# R40 register map
Vendor: Allwinner; Series: R40; File version: 0.1
CPU: CA7 0, little endian, MPU, FPU, double-precision FPU, 0 interrupt priority bits
Registers are 32-bit, read-write, reset 0x0 unless marked. A register's access mark holds for its fields unless they carry their own. Offsets are from the block's base; lines under a group give offsets from that group; [hi:lo] are bit positions; {n}, {i} and the like mark numbered series; 'fields as' and 'values as' point back to an identical list; <NAME> marks a mode.

## Memory map
0x01C00000 SYS_CTRL
0x01C02000 DMA
0x01C03000 NDFC
0x01C04000 TSC
0x01C05000 SPI0
0x01C06000 SPI1
0x01C09000 CSI0
0x01C0B000 EMAC
0x01C0F000 SMHC0
0x01C10000 SMHC1
0x01C11000 SMHC2
0x01C12000 SMHC3
0x01C15000 CE_NS
0x01C15800 CE_S
0x01C17000 SPI2
0x01C19000 USB1_HOST
0x01C1C000 USB2_HOST
0x01C1D000 CSI1
0x01C1F000 SPI3
0x01C20000 CCU
0x01C20400 RTC
0x01C20800 PIO
0x01C20C00 Timer
0x01C21000 OWA
0x01C21400 AC97
0x01C21800 CIR0
0x01C21C00 CIR1
0x01C22000 I2S/PCM0
0x01C22400 I2S/PCM1
0x01C22800 I2S/PCM2(for_HDMI)
0x01C22C00 Audio_Codec
0x01C23000 KeyPad
0x01C23400 PWM
0x01C24400 KEYADC
0x01C24C00 Thermal_Sensor
0x01C25000 RTP
0x01C25C00 CPU_Configuration
{0x1C28000+0x400*n} UART{n} (n=0..7)
0x01C2A000 PS2-0
0x01C2A400 PS2-1
0x01C2AC00 TWI0
0x01C2B000 TWI1
0x01C2B400 TWI2
0x01C2B800 TWI3
0x01C2C000 TWI4
0x01C2C400 SCR
0x01C30000 TVD_TOP
0x01C31000 TVD0
0x01C32000 TVD1
0x01C33000 TVD2
0x01C34000 TVD3
0x01C50000 GMAC
0x01C60000 High_Speed_Timer
0x01C70000 TCON_TOP
0x01C71000 TCON_LCD0
0x01C72000 TCON_LCD1
0x01C73000 TCON_TV0
0x01C74000 TCON_TV1
0x01C90000 TVE_TOP
0x01C94000 TVE0
0x01C98000 TVE1
0x01E80000 MP

## SYS_CTRL
Base 0x01C00000
0x00 SRAM_CTRL_REG0 reset 0x7FFFFFFF — 0x0000 SRAM Control Register 0
  [30:0] SRAM_C1_MAP — SRAM Area C1 50K Byte Configuration by AHB. 0: Map to CPU/DMA 1: Map to VE
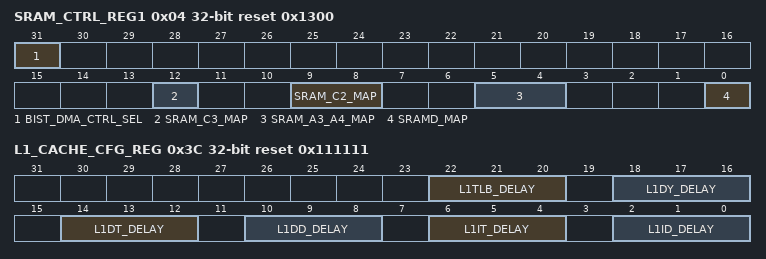
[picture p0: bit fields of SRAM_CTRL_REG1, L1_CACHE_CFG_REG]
0x04 SRAM_CTRL_REG1 reset 0x1300 — 0x0004 SRAM Control Register 1
  [31] BIST_DMA_CTRL_SEL — Bist and DMA control select. 0: DMA 1: Bist.
    0=DMA; 1=Bist
  [12] SRAM_C3_MAP — SRAM C3 map configuration. 0: Map to CPU/BIST 1: Map to ISP
    0=Map_to_CPU_slash_BIST (Map to CPU/BIST); 1=Map_to_ISP
  [9:8] SRAM_C2_MAP — SRAM C2 map configuration. 00: Map to CPU/BIST 01: Map to AE 10: Map to CE 11: Map to ACE
    0=Map_to_CPU_slash_BIST (Map to CPU/BIST); 1=Map_to_AE; 2=Map_to_CE; 3=Map_to_ACE
  [5:4] SRAM_A3_A4_MAP — SRAM Area A3/A4 Configuration by AHB. 00: Map to CPU/DMA 01: Map to EMAC 10: / 11: /
    0=Map_to_CPU_slash_DMA (Map to CPU/DMA); 1=Map_to_EMAC
  [0] SRAMD_MAP — SRAM D Area Config. 0: Map to CPU/DMA 1: Map to USB0
    0=Map_to_CPU_slash_DMA (Map to CPU/DMA); 1=Map_to_USB0
0x08 GPU_SRAM_TEST_CTRL_REG — 0x0008 GPU SRAM Control Register
  [7:0] GPU_SRAM_TEST_CTRL — GPU sram test control.
0x30 NMI_IRQ_CTRL_REG — NMI Interrupt Control Register
  [1:0] NMI_IRQ_SRC_TYPE — External NMI Interrupt Source Type. External NMI pin will be changed to alarm output if the power of I/O is switched off, and its power source is RTCVDD. 00: Low level sensitive 01: Negative edge trigged 10: High level sensitive 11: Positive edge sensitive
    0=Low level sensitive; 1=Negative edge trigged; 2=High level sensitive; 3=Positive edge sensitive
0x34 NMI_IRQ_PEND_REG — NMI Interrupt Pending Register
  [0] NMI_IRQ_SRC_PEND — NMI Source Pending and Clear Bit 0: NMI interrupt is not pending 1: NMI interrupt is pending
    0=not_pending (NMI interrupt is not pending); 1=pending (NMI interrupt is pending)
0x38 NMI_IRQ_ENABLE_REG — NMI Interrupt Enable Register
  [0] NMI_IRQ_SRC_ENABLE — NMI Source Enable and Disable Bit. 0: NMI interrupt is disable 1: NMI interrupt is enable
    0=disable (NMI interrupt is disable); 1=enable (NMI interrupt is enable)
0x3C L1_CACHE_CFG_REG reset 0x111111
  [22:20] L1TLB_DELAY, [18:16] L1DY_DELAY, [14:12] L1DT_DELAY, [10:8] L1DD_DELAY, [6:4] L1IT_DELAY, [2:0] L1ID_DELAY
0x44 L2_CFG_REG reset 0x22220000 (reset mask 0xFFFF0000) — L2 Cache Configuration Register
0xB8 BOOT_CPU_HP_FLAG_REG — Boot CPU Hot Plug Flag Register
  [31:0] BOOT — Boot CPU software flag when acting from hot plug.
0xBC CPU_SOFT_ENT_REG0 — CPU Software Entry Register 0
  [31:0] BOOT — Boot CPU software entry register when acting from hot plug or Non-boot CPU software entry register.

## Licence text in the file
questionable
